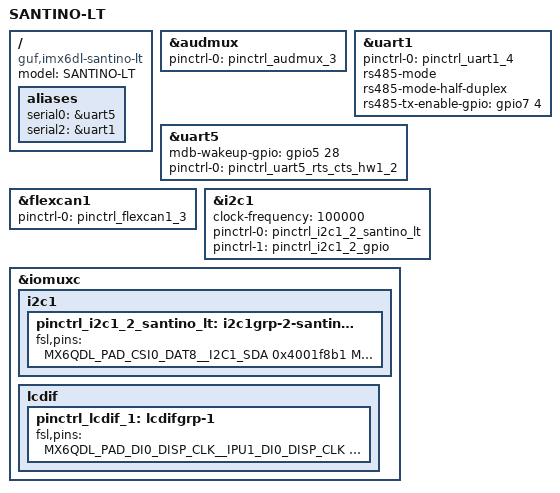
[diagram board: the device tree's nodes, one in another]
/*
 * Copyright (C) 2015 Garz & Fricke GmbH
 *
 * This program is free software; you can redistribute it and/or modify
 * it under the terms of the GNU General Public License version 2 as
 * published by the Free Software Foundation.
 */

/dts-v1/;

#include "imx6dl-guf.dtsi"
#include "imx6dl-guf-santino-common.dtsi"

/ {
	model = "SANTINO-LT";
	compatible = "guf,imx6dl-santino-lt", "fsl,imx6dl";

	aliases {
		serial0 = &uart5;
		serial2 = &uart1;
	};

};

&audmux {
	pinctrl-names = "default";
	pinctrl-0 = <&pinctrl_audmux_3>;
	status = "okay";
};

&uart1 {
	pinctrl-names = "default";
	pinctrl-0 = <&pinctrl_uart1_4>;
	status = "okay";

	rs485-mode;
	rs485-mode-half-duplex;
	rs485-tx-enable-gpio = <&gpio7 4 0>;
};

&uart5 {
	/* 
	 * Driver imx-mdb-guf should be used here because this is the MDB port.
	 * However, MDB and Debug-RS232 ports are using the same UART, so we cannot
	 * use an external kernel module for this interface, otherwise we would not
	 * see any boot messages. Thus we do not have MDB support for now.
	 */
	// compatible = "fsl,imx-mdb-guf";
	mdb-wakeup-gpio = <&gpio5 28 0>;

	pinctrl-names = "default";
	pinctrl-0 = <&pinctrl_uart5_rts_cts_hw1_2>;
	status = "okay";
};

&flexcan1 {
	pinctrl-names = "default";
	pinctrl-0 = <&pinctrl_flexcan1_3>;
	status = "okay";
};

&i2c1 {
	/* 
	 * External pull-up resistors are missing in hardware design, so we have to
	 * lower the frequency and enable stronger internal pull-ups.
	 */
	clock-frequency = <100000>;
	pinctrl-0 = <&pinctrl_i2c1_2_santino_lt>;
	pinctrl-1 = <&pinctrl_i2c1_2_gpio>;
};

&iomuxc {
	i2c1 {
		pinctrl_i2c1_2_santino_lt: i2c1grp-2-santino-lt {
			fsl,pins = <
				MX6QDL_PAD_CSI0_DAT8__I2C1_SDA 0x4001f8b1	/* 22k pull-up */
				MX6QDL_PAD_CSI0_DAT9__I2C1_SCL 0x4001f8b1	/* 22k pull-up */
			>;
		};
	};

	lcdif {
		pinctrl_lcdif_1: lcdifgrp-1 {
			fsl,pins = <
				MX6QDL_PAD_DI0_DISP_CLK__IPU1_DI0_DISP_CLK	0x80000000
				MX6QDL_PAD_DI0_PIN15__LCD_ENABLE			0x80000000
				MX6QDL_PAD_DI0_PIN2__LCD_HSYNC				0x80000000
				MX6QDL_PAD_DI0_PIN3__LCD_VSYNC				0x80000000
				MX6QDL_PAD_DISP0_DAT0__IPU1_DISP0_DATA00	0x80000000
				MX6QDL_PAD_DISP0_DAT1__IPU1_DISP0_DATA01	0x80000000
				MX6QDL_PAD_DISP0_DAT2__IPU1_DISP0_DATA02	0x80000000
				MX6QDL_PAD_DISP0_DAT3__IPU1_DISP0_DATA03	0x80000000
				MX6QDL_PAD_DISP0_DAT4__IPU1_DISP0_DATA04	0x80000000
				MX6QDL_PAD_DISP0_DAT5__IPU1_DISP0_DATA05	0x80000000
				MX6QDL_PAD_DISP0_DAT6__IPU1_DISP0_DATA06	0x80000000
				MX6QDL_PAD_DISP0_DAT7__IPU1_DISP0_DATA07	0x80000000
				MX6QDL_PAD_DISP0_DAT8__IPU1_DISP0_DATA08	0x80000000
				MX6QDL_PAD_DISP0_DAT9__IPU1_DISP0_DATA09	0x80000000
				MX6QDL_PAD_DISP0_DAT10__IPU1_DISP0_DATA10	0x80000000
				MX6QDL_PAD_DISP0_DAT11__IPU1_DISP0_DATA11	0x80000000
				MX6QDL_PAD_DISP0_DAT12__IPU1_DISP0_DATA12	0x80000000
				MX6QDL_PAD_DISP0_DAT13__IPU1_DISP0_DATA13	0x80000000
				MX6QDL_PAD_DISP0_DAT14__IPU1_DISP0_DATA14	0x80000000
				MX6QDL_PAD_DISP0_DAT15__IPU1_DISP0_DATA15	0x80000000
				MX6QDL_PAD_DISP0_DAT16__IPU1_DISP0_DATA16	0x80000000
				MX6QDL_PAD_DISP0_DAT17__IPU1_DISP0_DATA17	0x80000000
			>;
		};
	};
};
